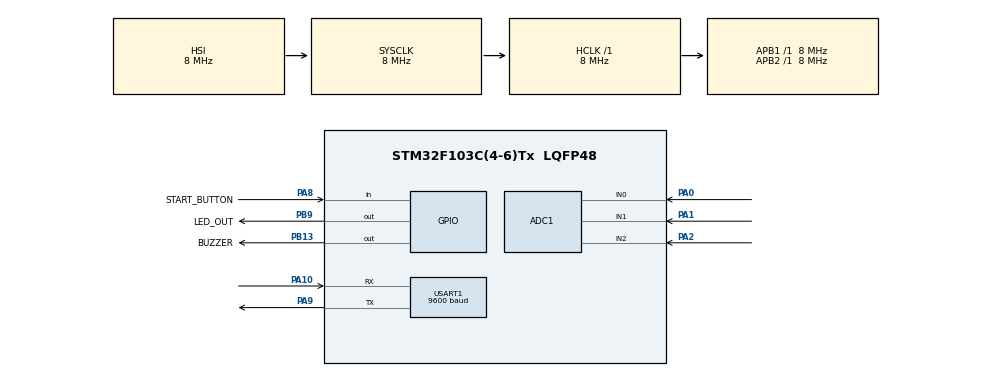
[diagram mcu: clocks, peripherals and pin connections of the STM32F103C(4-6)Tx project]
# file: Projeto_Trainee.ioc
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Mcu.Family=STM32F1
RCC.PLLSourceVirtual=RCC_PLLSOURCE_HSE
Dma.ADC1.0.Instance=DMA1_Channel1
ADC1.Rank-0\#ChannelRegularConversion=1
PD1-OSC_OUT.Mode=HSE-External-Oscillator
PB9.GPIO_Label=LED_OUT
PA10.Mode=Asynchronous
ADC1.ContinuousConvMode=ENABLE
USART1.BaudRate=9600
SH.ADCx_IN2.0=ADC1_IN2,IN2
PD0-OSC_IN.Signal=RCC_OSC_IN
PB13.GPIO_Label=BUZZER
PB13.Signal=GPIO_Output
ADC1.SamplingTime-2\#ChannelRegularConversion=ADC_SAMPLETIME_28CYCLES_5
ProjectManager.StackSize=0x400
PA0-WKUP.Signal=ADCx_IN0
PD1-OSC_OUT.Signal=RCC_OSC_OUT
PA13.Signal=SYS_JTMS-SWDIO
Dma.ADC1.0.PeriphDataAlignment=DMA_PDATAALIGN_WORD
PA9.Mode=Asynchronous
PA8.GPIO_Label=START_BUTTON
ProjectManager.TargetToolchain=STM32CubeIDE
Dma.ADC1.0.Mode=DMA_CIRCULAR
RCC.HCLKFreq_Value=8000000
Dma.ADC1.0.Priority=DMA_PRIORITY_LOW
RCC.APB2TimFreq_Value=8000000
PA9.Signal=USART1_TX
ADC1.Channel-1\#ChannelRegularConversion=ADC_CHANNEL_1
Dma.ADC1.0.Direction=DMA_PERIPH_TO_MEMORY
ADC1.Channel-2\#ChannelRegularConversion=ADC_CHANNEL_2
ADC1.InjNumberOfConversion=3
RCC.USBFreq_Value=16000000
Dma.ADC1.0.MemDataAlignment=DMA_MDATAALIGN_WORD
PA1.Signal=ADCx_IN1
RCC.AHBFreq_Value=8000000
PD0-OSC_IN.Mode=HSE-External-Oscillator
ADC1.Channel-0\#ChannelRegularConversion=ADC_CHANNEL_0
board=custom
RCC.APB2Freq_Value=8000000
ADC1.Rank-2\#ChannelRegularConversion=3
PA14.Mode=Serial_Wire
Dma.ADC1.0.PeriphInc=DMA_PINC_DISABLE
PA8.Signal=GPIO_Input
SH.ADCx_IN0.0=ADC1_IN0,IN0
ADC1.NbrOfConversion=3
PA13.Mode=Serial_Wire
Mcu.Name=STM32F103C(4-6)Tx
ADC1.SamplingTime-0\#ChannelRegularConversion=ADC_SAMPLETIME_28CYCLES_5
PA2.Signal=ADCx_IN2
ADC1.SamplingTime-1\#ChannelRegularConversion=ADC_SAMPLETIME_28CYCLES_5
RCC.SYSCLKFreq_VALUE=8000000
Mcu.Package=LQFP48
PB9.Signal=GPIO_Output
ADC1.master=1
ADC1.EnableInjectedConversion=DISABLE
USART1.VirtualMode=VM_ASYNC
ADC1.Rank-1\#ChannelRegularConversion=2
PA10.Signal=USART1_RX
PA14.Signal=SYS_JTCK-SWCLK
Dma.ADC1.0.MemInc=DMA_MINC_ENABLE
ProjectManager.HeapSize=0x200
NVIC.PriorityGroup=NVIC_PRIORITYGROUP_4
ADC1.NbrOfConversionFlag=1
SH.ADCx_IN1.0=ADC1_IN1,IN1
RCC.APB1TimFreq_Value=8000000
NVIC.DMA1_Channel1_IRQn=true\:0\:0\:false\:false\:true\:false\:true
Dma.Request0=ADC1
RCC.APB1Freq_Value=8000000

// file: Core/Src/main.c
/* USER CODE BEGIN Header */
/**
  ******************************************************************************
  * @file           : main.c
  * @brief          : Main program body
  ******************************************************************************
  * @attention
  *
  * <h2><center>&copy; Copyright (c) 2021 STMicroelectronics.
  * All rights reserved.</center></h2>
  *
  * This software component is licensed by ST under BSD 3-Clause license,
  * the "License"; You may not use this file except in compliance with the
  * License. You may obtain a copy of the License at:
  *                        opensource.org/licenses/BSD-3-Clause
  *
  ******************************************************************************
  */
/* USER CODE END Header */
#include "main.h"
/* USER CODE BEGIN Includes */

#include "adc.h"
#include "uart.h"
#include "securityElements.h"

/* USER CODE END Includes */

ADC_HandleTypeDef hadc1;
DMA_HandleTypeDef hdma_adc1;

UART_HandleTypeDef huart1;

/* USER CODE BEGIN PV */

adc_t adc;
uart_t uart;
errors_t errors;

/* USER CODE END PV */

void SystemClock_Config(void);
static void MX_GPIO_Init(void);
static void MX_DMA_Init(void);
static void MX_ADC1_Init(void);
static void MX_USART1_UART_Init(void);

int main(void)
{

  /* MCU Configuration--------------------------------------------------------*/

  /* Reset of all peripherals, Initializes the Flash interface and the Systick. */
  HAL_Init();

  /* Configure the system clock */
  SystemClock_Config();

  /* Initialize all configured peripherals */
  MX_GPIO_Init();
  MX_DMA_Init();
  MX_ADC1_Init();
  MX_USART1_UART_Init();
  /* USER CODE BEGIN 2 */

  startProtocol(); //Chama o protocolo para inicialização
  ADC_Init(adc.buffer); //Inicialização do ADC

  /* USER CODE END 2 */

  /* Infinite loop */
  while (1)
  {

    /* USER CODE BEGIN 3 */

	  HAL_GPIO_WritePin(GPIOB, GPIO_PIN_9, GPIO_PIN_RESET);

  }
  /* USER CODE END 3 */
}

void SystemClock_Config(void)
{
  RCC_OscInitTypeDef RCC_OscInitStruct = {0};
  RCC_ClkInitTypeDef RCC_ClkInitStruct = {0};
  RCC_PeriphCLKInitTypeDef PeriphClkInit = {0};

  /** Initializes the RCC Oscillators according to the specified parameters
  * in the RCC_OscInitTypeDef structure.
  */
  RCC_OscInitStruct.OscillatorType = RCC_OSCILLATORTYPE_HSI;
  RCC_OscInitStruct.HSIState = RCC_HSI_ON;
  RCC_OscInitStruct.HSICalibrationValue = RCC_HSICALIBRATION_DEFAULT;
  RCC_OscInitStruct.PLL.PLLState = RCC_PLL_NONE;
  if (HAL_RCC_OscConfig(&RCC_OscInitStruct) != HAL_OK)
  {
    Error_Handler();
  }
  /** Initializes the CPU, AHB and APB buses clocks
  */
  RCC_ClkInitStruct.ClockType = RCC_CLOCKTYPE_HCLK|RCC_CLOCKTYPE_SYSCLK
                              |RCC_CLOCKTYPE_PCLK1|RCC_CLOCKTYPE_PCLK2;
  RCC_ClkInitStruct.SYSCLKSource = RCC_SYSCLKSOURCE_HSI;
  RCC_ClkInitStruct.AHBCLKDivider = RCC_SYSCLK_DIV1;
  RCC_ClkInitStruct.APB1CLKDivider = RCC_HCLK_DIV1;
  RCC_ClkInitStruct.APB2CLKDivider = RCC_HCLK_DIV1;

  if (HAL_RCC_ClockConfig(&RCC_ClkInitStruct, FLASH_LATENCY_0) != HAL_OK)
  {
    Error_Handler();
  }
  PeriphClkInit.PeriphClockSelection = RCC_PERIPHCLK_ADC;
  PeriphClkInit.AdcClockSelection = RCC_ADCPCLK2_DIV2;
  if (HAL_RCCEx_PeriphCLKConfig(&PeriphClkInit) != HAL_OK)
  {
    Error_Handler();
  }
}

static void MX_ADC1_Init(void)
{

  ADC_ChannelConfTypeDef sConfig = {0};

  /** Common config
  */
  hadc1.Instance = ADC1;
  hadc1.Init.ScanConvMode = ADC_SCAN_ENABLE;
  hadc1.Init.ContinuousConvMode = ENABLE;
  hadc1.Init.DiscontinuousConvMode = DISABLE;
  hadc1.Init.ExternalTrigConv = ADC_SOFTWARE_START;
  hadc1.Init.DataAlign = ADC_DATAALIGN_RIGHT;
  hadc1.Init.NbrOfConversion = 3;
  if (HAL_ADC_Init(&hadc1) != HAL_OK)
  {
    Error_Handler();
  }
  /** Configure Regular Channel
  */
  sConfig.Channel = ADC_CHANNEL_0;
  sConfig.Rank = ADC_REGULAR_RANK_1;
  sConfig.SamplingTime = ADC_SAMPLETIME_71CYCLES_5;
  if (HAL_ADC_ConfigChannel(&hadc1, &sConfig) != HAL_OK)
  {
    Error_Handler();
  }
  /** Configure Regular Channel
  */
  sConfig.Channel = ADC_CHANNEL_1;
  sConfig.Rank = ADC_REGULAR_RANK_2;
  if (HAL_ADC_ConfigChannel(&hadc1, &sConfig) != HAL_OK)
  {
    Error_Handler();
  }
  /** Configure Regular Channel
  */
  sConfig.Channel = ADC_CHANNEL_2;
  sConfig.Rank = ADC_REGULAR_RANK_3;
  if (HAL_ADC_ConfigChannel(&hadc1, &sConfig) != HAL_OK)
  {
    Error_Handler();
  }

}

static void MX_USART1_UART_Init(void)
{

  huart1.Instance = USART1;
  huart1.Init.BaudRate = 9600;
  huart1.Init.WordLength = UART_WORDLENGTH_8B;
  huart1.Init.StopBits = UART_STOPBITS_1;
  huart1.Init.Parity = UART_PARITY_NONE;
  huart1.Init.Mode = UART_MODE_TX_RX;
  huart1.Init.HwFlowCtl = UART_HWCONTROL_NONE;
  huart1.Init.OverSampling = UART_OVERSAMPLING_16;
  if (HAL_UART_Init(&huart1) != HAL_OK)
  {
    Error_Handler();
  }

}

static void MX_DMA_Init(void)
{

  /* DMA controller clock enable */
  __HAL_RCC_DMA1_CLK_ENABLE();

  /* DMA interrupt init */
  /* DMA1_Channel1_IRQn interrupt configuration */
  HAL_NVIC_SetPriority(DMA1_Channel1_IRQn, 0, 0);
  HAL_NVIC_EnableIRQ(DMA1_Channel1_IRQn);

}

static void MX_GPIO_Init(void)
{
  GPIO_InitTypeDef GPIO_InitStruct = {0};

  /* GPIO Ports Clock Enable */
  __HAL_RCC_GPIOD_CLK_ENABLE();
  __HAL_RCC_GPIOA_CLK_ENABLE();
  __HAL_RCC_GPIOB_CLK_ENABLE();

  /*Configure GPIO pin Output Level */
  HAL_GPIO_WritePin(GPIOB, BUZZER_Pin|LED_OUT_Pin, GPIO_PIN_RESET);

  /*Configure GPIO pins : BUZZER_Pin LED_OUT_Pin */
  GPIO_InitStruct.Pin = BUZZER_Pin|LED_OUT_Pin;
  GPIO_InitStruct.Mode = GPIO_MODE_OUTPUT_PP;
  GPIO_InitStruct.Pull = GPIO_NOPULL;
  GPIO_InitStruct.Speed = GPIO_SPEED_FREQ_LOW;
  HAL_GPIO_Init(GPIOB, &GPIO_InitStruct);

  /*Configure GPIO pin : START_BUTTON_Pin */
  GPIO_InitStruct.Pin = START_BUTTON_Pin;
  GPIO_InitStruct.Mode = GPIO_MODE_INPUT;
  GPIO_InitStruct.Pull = GPIO_NOPULL;
  HAL_GPIO_Init(START_BUTTON_GPIO_Port, &GPIO_InitStruct);

}

/* USER CODE BEGIN 4 */

//A função de CallBack do ADC foi movida para a pasta adc.c de modo a aumentar
//a modularização do código

/* USER CODE END 4 */

void Error_Handler(void)
{
  __disable_irq();
  while (1)
  {
  }
}

/************************ (C) COPYRIGHT STMicroelectronics *****END OF FILE****/
